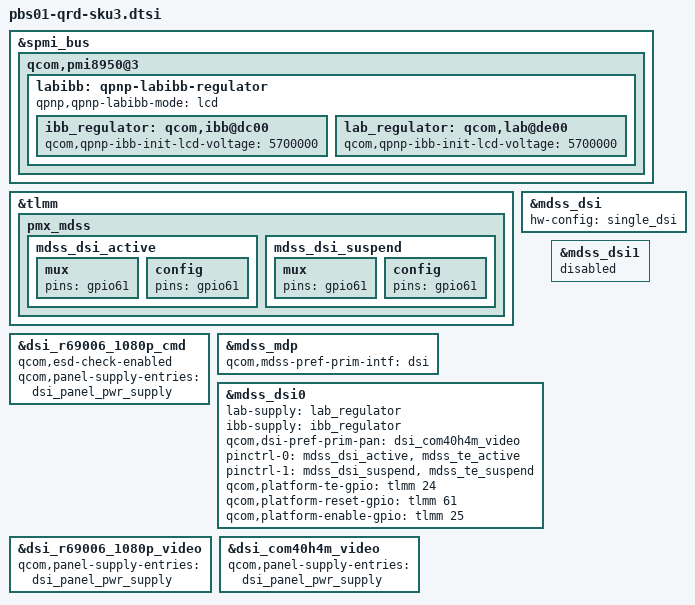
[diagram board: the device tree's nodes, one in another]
/*
 * Copyright (c) 2015-2016, The Linux Foundation. All rights reserved.
 *
 * This program is free software; you can redistribute it and/or modify
 * it under the terms of the GNU General Public License version 2 and
 * only version 2 as published by the Free Software Foundation.
 *
 * This program is distributed in the hope that it will be useful,
 * but WITHOUT ANY WARRANTY; without even the implied warranty of
 * MERCHANTABILITY or FITNESS FOR A PARTICULAR PURPOSE.  See the
 * GNU General Public License for more details.
 */

#include "pbs01-qrd.dtsi"

&spmi_bus {
	qcom,pmi8950@3 {
		labibb: qpnp-labibb-regulator {
			ibb_regulator: qcom,ibb@dc00 {
				/delete-property/
					qcom,qpnp-ibb-use-default-voltage;
				qcom,qpnp-ibb-init-lcd-voltage = <5700000>;
			};

			lab_regulator: qcom,lab@de00 {
				/delete-property/
					qcom,qpnp-ibb-use-default-voltage;
				qcom,qpnp-ibb-init-lcd-voltage = <5700000>;
			};
		};
	};
};

#include "msm8953-mdss-panels.dtsi"

&tlmm {
	pmx_mdss {
		mdss_dsi_active: mdss_dsi_active {
			mux {
				pins = "gpio61";
			};
			config {
				pins = "gpio61";
			};
		};
		mdss_dsi_suspend: mdss_dsi_suspend {
			mux {
				pins = "gpio61";
			};
			config {
				pins = "gpio61";
			};
		};
	};
};

&dsi_r69006_1080p_cmd {
	qcom,esd-check-enabled;
};

&mdss_mdp {
	qcom,mdss-pref-prim-intf = "dsi";
};

&mdss_dsi {
	hw-config = "single_dsi";
};

&mdss_dsi0 {
	lab-supply = <&lab_regulator>;
	ibb-supply = <&ibb_regulator>;
	/delete-property/ vdd-supply;

	qcom,dsi-pref-prim-pan = <&dsi_com40h4m_video>;
	pinctrl-names = "mdss_default", "mdss_sleep";
	pinctrl-0 = <&mdss_dsi_active &mdss_te_active>;
	pinctrl-1 = <&mdss_dsi_suspend &mdss_te_suspend>;
	qcom,platform-te-gpio = <&tlmm 24 0>;
	qcom,platform-reset-gpio = <&tlmm 61 0>;
	qcom,platform-enable-gpio  = <&tlmm 25 0>;
};

&mdss_dsi1 {
	status = "disabled";
};

&labibb {
	status = "ok";
	qpnp,qpnp-labibb-mode = "lcd";
};

&dsi_r69006_1080p_cmd {
	qcom,panel-supply-entries = <&dsi_panel_pwr_supply>;
};

&dsi_r69006_1080p_video {
	qcom,panel-supply-entries = <&dsi_panel_pwr_supply>;
};
&dsi_com40h4m_video {
	/delete-property/ lab-supply;
	/delete-property/ ibb-supply;
	qcom,panel-supply-entries = <&dsi_panel_pwr_supply>;
};


